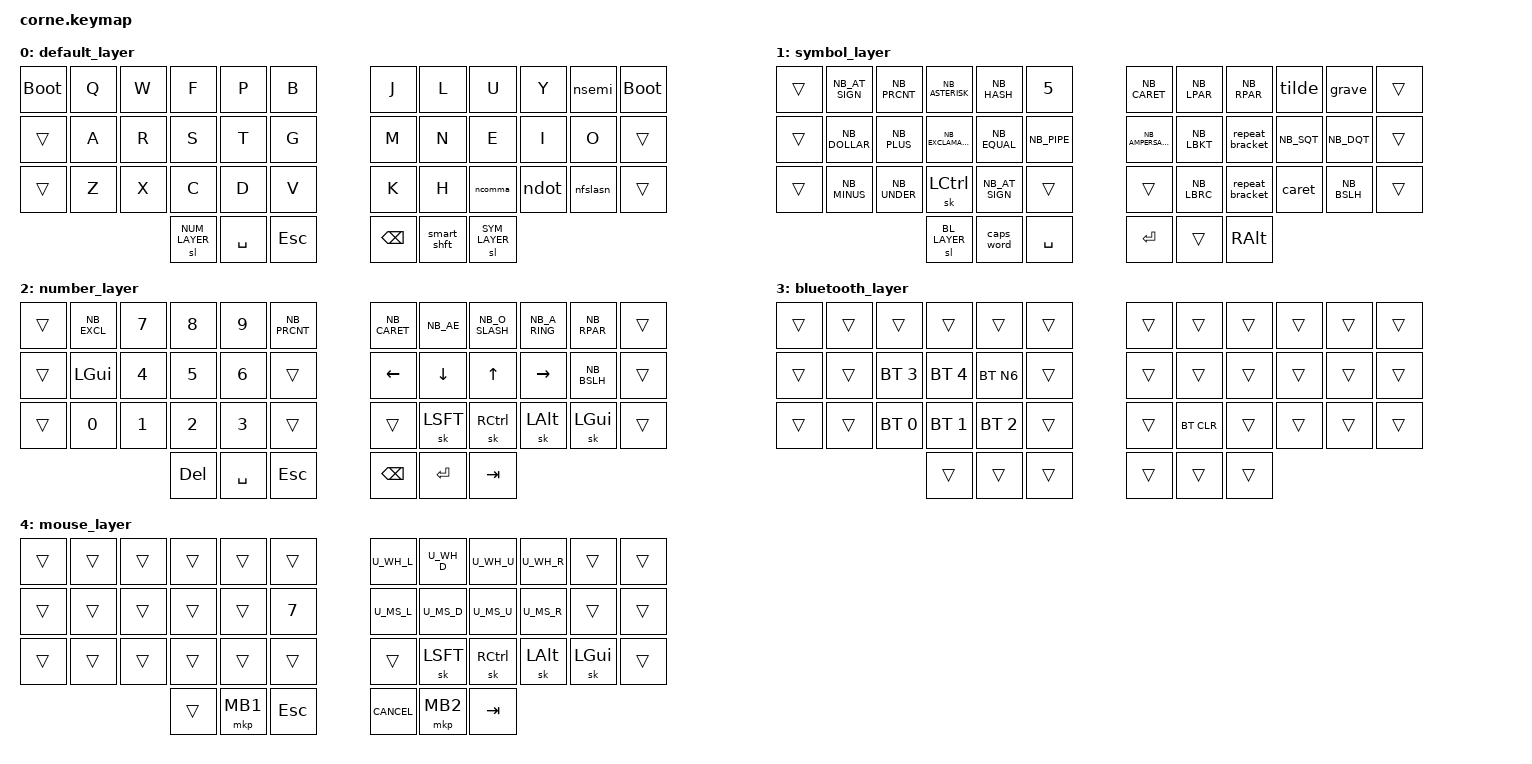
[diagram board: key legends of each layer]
/*
 * Copyright (c) 2020 The ZMK Contributors
 *
 * SPDX-License-Identifier: MIT
 */

#include <behaviors.dtsi>
#include <behaviors/num_word.dtsi> // requires auto-layer module
#include <dt-bindings/zmk/keys.h>
#include <dt-bindings/zmk/bt.h>
#include "zmk-helpers/helper.h"
#include "includes/settings.dtsi"
#include "includes/mouse.dtsi"
#include <behaviors/mouse_keys.dtsi>
#include "keys_nb.h"

#define DEF_LAYER 0
#define SYM_LAYER 1
#define NUM_LAYER 2
#define BL_LAYER 3
#define MOUSE_LAYER 4

#define QUICK_TAP_MS 175

ZMK_MOD_MORPH(smart_shft,
    bindings = <&sk LSHFT>, <&caps_word>;
    mods = <(MOD_LSFT)>;
)
&caps_word {  // mods deactivate caps-word, requires PR #1451
    /delete-property/ ignore-modifiers;
      continue-list = <NB_UNDER NB_MINUS DELETE BACKSPACE>;
};


// tap: num-word | double-tap: sticky num-layer | hold: num-layer
#define SMART_NUM &smart_num NUM_LAYER 0
ZMK_HOLD_TAP(smart_num,
    flavor = "balanced";
    tapping-term-ms = <200>;
    quick-tap-ms = <QUICK_TAP_MS>;
    bindings = <&mo>, <&num_dance>;
)
ZMK_TAP_DANCE(num_dance,
    tapping-term-ms = <200>;
    bindings = <&num_word NUM_LAYER>, <&sl NUM_LAYER>;  // reverse this for sticky-num on single tap
)


&lt {
        require-prior-idle-ms = <0>;
        tapping-term-ms = <125>;
        quick-tap-ms = <0>;
};

&sk { 
        release-after-ms = <86400000>; // Default is 1000 ms, raised to 1 day to emulate Callum's behavior that requires canceling on layer key.
    };

/ {
    behaviors {
        ncomma: norwegian_comma {
            compatible = "zmk,behavior-mod-morph";
            #binding-cells = <0>;
            bindings = <&kp NB_COMMA>, <&kp NB_LESS_THAN>;
            mods = <(MOD_LSFT|MOD_RSFT)>;
        };
        ndot: norwegian_dot {
            compatible = "zmk,behavior-mod-morph";
            #binding-cells = <0>;
            bindings = <&kp NB_DOT>, <&kp NB_GREATER_THAN>;
            mods = <(MOD_LSFT|MOD_RSFT)>;
        };
        nfslasn: norwegian_forward_slash {
            compatible = "zmk,behavior-mod-morph";
            #binding-cells = <0>;
            bindings = <&kp NB_FSLH>, <&kp NB_QUESTION>;
            mods = <(MOD_LSFT|MOD_RSFT)>;
        };
        nsemi: norwegian_semi {
            compatible = "zmk,behavior-mod-morph";
            #binding-cells = <0>;
            bindings = <&kp NB_SEMI>, <&kp NB_COLON>;
            mods = <(MOD_LSFT|MOD_RSFT)>;
        };
        repeat_bracket: repeat_bracket {
            compatible = "zmk,behavior-mod-morph";
            #binding-cells = <0>;
            bindings = <&kp NB_RBKT>, <&kp NB_RBKT>;
            mods = <(MOD_LSFT|MOD_RSFT)>;
        };
    };
     combos {
        compatible = "zmk,combos";
        // combo_tmux {
        //     timeout-ms = <200>;
        //     key-positions = <37 40>;
        //     bindings = <&tmux>;
        // };
        combo_mouse {
            timeout-ms = <100>;
            key-positions = <38 39>;
            bindings = <&tog MOUSE_LAYER>;
        };
    };
    macros {
       //  tmux: tmux {
       //         label = "TMUX";
       //         compatible = "zmk,behavior-macro";
       //         #binding-cells = <0>;
       //         tap-ms = <0>;
       //         wait-ms = <0>;
       //         bindings
       //             = <&macro_press &kp LCTL>
       //             , <&macro_tap &kp SPACE>
       //             , <&macro_release &kp LCTL>
       //             ;
       // };
        tilde: tilde {
               label = "TILDE";
               compatible = "zmk,behavior-macro";
               #binding-cells = <0>;
               tap-ms = <0>;
               wait-ms = <0>;
               bindings
                   = <&macro_tap &kp NB_TILDE>
                   , <&macro_tap &kp NB_TILDE>
                   ;
       };
       grave: grave {
              label = "grave";
              compatible = "zmk,behavior-macro";
              #binding-cells = <0>;
              tap-ms = <0>;
              wait-ms = <0>;
              bindings
                   = <&macro_tap &kp NB_GRAVE>
                   , <&macro_tap &kp NB_GRAVE>
               ;
        };
       caret: caret {
              label = "caret";
              compatible = "zmk,behavior-macro";
              #binding-cells = <0>;
              tap-ms = <0>;
              wait-ms = <0>;
              bindings
                   = <&macro_tap &kp NB_CARET>
                   , <&macro_tap &kp NB_CARET>
               ;
        };
    };

    keymap {
        compatible = "zmk,keymap";

        default_layer {
            bindings = <
                &bootloader &kp Q &kp W &kp F &kp P &kp B        &kp J &kp L  &kp U &kp Y &nsemi &bootloader
                &trans &kp A &kp R &kp S &kp T &kp G        &kp M &kp N &kp E &kp I &kp O &trans
                &trans &kp Z &kp X &kp C &kp D &kp V      &kp K &kp H &ncomma &ndot &nfslasn &trans
                &sl NUM_LAYER &kp SPACE &kp ESC     &kp BSPC &smart_shft &sl SYM_LAYER
            >;
        };

        symbol_layer {
            bindings = <
                &trans &kp NB_AT_SIGN &kp NB_PRCNT &kp NB_ASTERISK &kp NB_HASH &kp N5   &kp NB_CARET &kp NB_LPAR &kp NB_RPAR &tilde &grave &trans
                &trans &kp NB_DOLLAR &kp NB_PLUS &kp NB_EXCLAMATION  &kp NB_EQUAL &kp NB_PIPE   &kp NB_AMPERSAND &kp NB_LBKT &repeat_bracket &kp NB_SQT &kp NB_DQT &trans
                &trans &kp NB_MINUS &kp NB_UNDER &sk LCTL &kp NB_AT_SIGN &trans   &trans &kp NB_LBRC &repeat_bracket &caret &kp NB_BSLH &trans
                &sl BL_LAYER &caps_word &kp SPACE &kp RET &trans &kp RALT
            >;
        };

        number_layer {
            bindings = <
                &trans &kp NB_EXCL &kp N7 &kp N8 &kp N9 &kp NB_PRCNT   &kp NB_CARET &kp NB_AE &kp NB_O_SLASH &kp NB_A_RING &kp NB_RPAR &trans
                &trans &kp LGUI &kp N4 &kp N5 &kp N6 &trans   &kp LEFT &kp DOWN &kp UP &kp RIGHT &kp NB_BSLH &trans
                &trans &kp N0 &kp N1 &kp N2 &kp N3 &trans       &trans &sk LSFT &sk RCTL &sk LALT &sk LGUI &trans 
                &kp DEL &kp SPACE &kp ESC      &kp BSPC &kp RET &kp TAB
            >;
        };

        bluetooth_layer {
            bindings = <
                &trans &trans &trans &trans &trans &trans   &trans &trans &trans &trans &trans &trans
                &trans &trans &bt BT_SEL 3 &bt BT_SEL 4 &bt N6 &trans   &trans &trans &trans &trans &trans &trans
                &trans &trans &bt BT_SEL 0 &bt BT_SEL 1 &bt BT_SEL 2 &trans   &trans &bt BT_CLR &trans &trans &trans &trans
                            &trans &trans &trans   &trans &trans &trans

            >;
        };

        mouse_layer {
            bindings = <
                &trans &trans &trans &trans &trans &trans   U_WH_L U_WH_D U_WH_U U_WH_R &trans &trans
                &trans &trans &trans &trans &trans &kp N7   U_MS_L U_MS_D U_MS_U U_MS_R &trans &trans
                &trans &trans &trans &trans &trans &trans   &trans &sk LSFT &sk RCTL &sk LALT &sk LGUI &trans 
                &trans &mkp MB1 &kp ESC      &kp K_CANCEL &mkp MB2 &kp TAB
            >;
        };

    };
};

/* vim: set ft=c tw=174: */
